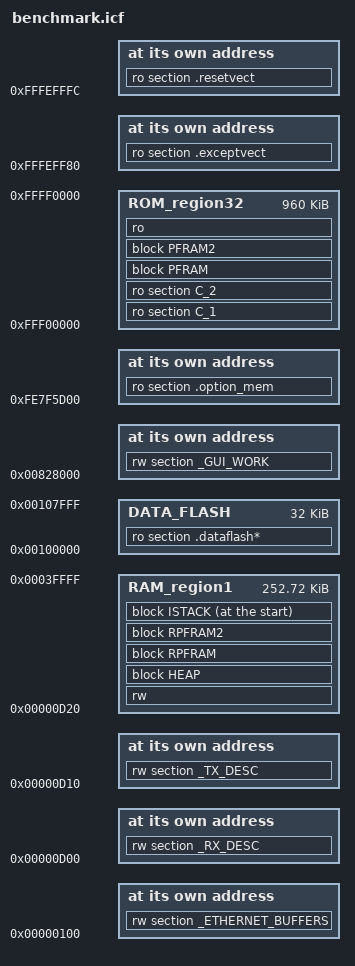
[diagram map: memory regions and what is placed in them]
//-----------------------------------------------------------------------------
// Linker configuration file for the Renesas RX65N Envision Kit
// benchmark Demo program
//-----------------------------------------------------------------------------
// Compatibility check
define exported symbol __link_file_version_4 = 1;

define memory mem with size = 4G;

define region RAM_region1  = mem:[from 0x00000D20 to 0x0003FFFF];

define region ROM_region32 = mem:[from 0xFFF00000 to 0xFFFF0000];

define region DATA_FLASH   = mem:[from 0x00100000 to 0x00107FFF];

initialize manually { ro section FRAM, ro section FRAM2, rw section .textrw };
initialize by copy { rw, ro section D, ro section D_1, ro section D_2 };
do not initialize  { section .*.noinit };

define block HEAP     with alignment = 4, size = _HEAP_SIZE { };
define block ISTACK   with alignment = 4, size = _ISTACK_SIZE { };

define block PFRAM   { ro section FRAM_init };
define block RPFRAM  { rw section FRAM };
define block PFRAM2  { ro section FRAM2_init };
define block RPFRAM2 { rw section FRAM2 };

place at address mem:0xFE7F5D00      { ro section .option_mem };

//place at address mem:0xFFFFFF80      { ro section .exceptvect };
//place at address mem:0xFFFFFFFC      { ro section .resetvect };

// Use these adresses for the image that should be loaded with secure boot
place at address mem:0xFFFEFF80      { ro section .exceptvect };
place at address mem:0xFFFEFFFC      { ro section .resetvect };

place at address mem:0x00000100      { rw section _ETHERNET_BUFFERS };
place at address mem:0x00000D00      { rw section _RX_DESC };
place at address mem:0x00000D10      { rw section _TX_DESC };

place at address mem:0x00828000      { rw section _GUI_WORK };

"ROM32":place in ROM_region32        { ro section C_1,
                                       ro section C_2,
                                       block PFRAM,
                                       block PFRAM2,                                       
                                       ro };

"RAM32":place in RAM_region1        { rw,
                                      block HEAP,
                                      block RPFRAM,
                                      block RPFRAM2 };

"STACKS":place at start of RAM_region1 { block ISTACK };

"DATAFLASH":place in DATA_FLASH      { ro section .dataflash* };
                                     
                                     

